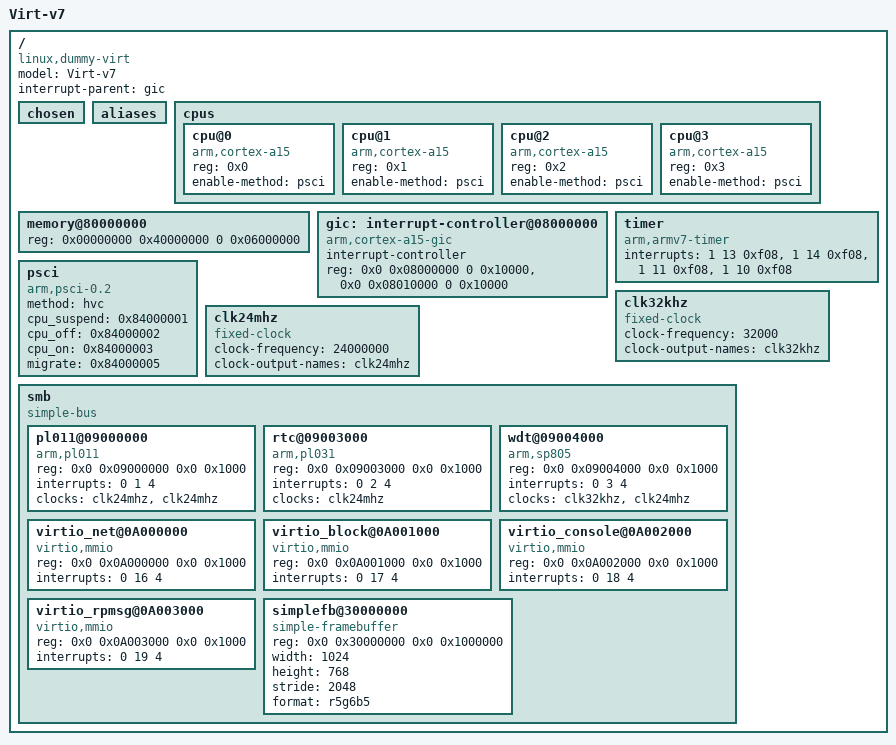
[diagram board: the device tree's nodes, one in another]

/dts-v1/;

/ {
	model = "Virt-v7";
	compatible = "linux,dummy-virt";
	interrupt-parent = <&gic>;
	#address-cells = <2>;
	#size-cells = <2>;

	chosen { };
	aliases { };

	cpus {
		#address-cells = <1>;
		#size-cells = <0>;

		cpu@0 {
			device_type = "cpu";
			compatible = "arm,cortex-a15";
			reg = <0x0>;
			enable-method = "psci";
		};
		cpu@1 {
			device_type = "cpu";
			compatible = "arm,cortex-a15";
			reg = <0x1>;
			enable-method = "psci";
		};
		cpu@2 {
			device_type = "cpu";
			compatible = "arm,cortex-a15";
			reg = <0x2>;
			enable-method = "psci";
		};
		cpu@3 {
			device_type = "cpu";
			compatible = "arm,cortex-a15";
			reg = <0x3>;
			enable-method = "psci";
		};
	};

	memory@80000000 {
		device_type = "memory";
		reg = <0x00000000 0x40000000 0 0x06000000>;
	};

	gic: interrupt-controller@08000000 {
		compatible = "arm,cortex-a15-gic";
		#interrupt-cells = <3>;
		#address-cells = <0>;
		interrupt-controller;
		reg = <0x0 0x08000000 0 0x10000>,
		      <0x0 0x08010000 0 0x10000>;
	};

	timer {
		compatible = "arm,armv7-timer";
		interrupts = <1 13 0xf08>,
			     <1 14 0xf08>,
			     <1 11 0xf08>,
			     <1 10 0xf08>;
	};

	psci {
		compatible = "arm,psci-0.2", "arm,psci";
		method = "hvc";
		cpu_suspend = <0x84000001>;
		cpu_off = <0x84000002>;
		cpu_on = <0x84000003>;
		migrate = <0x84000005>;
	};

	clk32khz: clk32khz {
		compatible = "fixed-clock";
		#clock-cells = <0x0>;
		clock-frequency = <32000>;
		clock-output-names = "clk32khz";
	};

	clk24mhz: clk24mhz {
		compatible = "fixed-clock";
		#clock-cells = <0x0>;
		clock-frequency = <24000000>;
		clock-output-names = "clk24mhz";
	};

	smb {
		compatible = "simple-bus";
		#address-cells = <2>;
		#size-cells = <2>;
		ranges;

		pl011@09000000 {
			compatible = "arm,pl011", "arm,primecell";
			reg = <0x0 0x09000000 0x0 0x1000>;
			interrupts = <0 1 4>;
			clocks = <&clk24mhz>, <&clk24mhz>;
			clock-names = "uartclk", "apb_pclk";
		};

		rtc@09003000 {
			compatible = "arm,pl031", "arm,primecell";
			reg = <0x0 0x09003000 0x0 0x1000>;
			interrupts = <0 2 4>;
			clocks = <&clk24mhz>;
			clock-names = "apb_pclk";
		};

		wdt@09004000 {
			compatible = "arm,sp805", "arm,primecell";
			reg = <0x0 0x09004000 0x0 0x1000>;
			interrupts = <0 3 4>;
			clocks = <&clk32khz>, <&clk24mhz>;
			clock-names = "wdogclk", "apb_pclk";
		};

		virtio_net@0A000000 {
			compatible = "virtio,mmio";
			reg = <0x0 0x0A000000 0x0 0x1000>;
			interrupts = <0 16 4>;
		};

		virtio_block@0A001000 {
			compatible = "virtio,mmio";
			reg = <0x0 0x0A001000 0x0 0x1000>;
			interrupts = <0 17 4>;
		};

		virtio_console@0A002000 {
			compatible = "virtio,mmio";
			reg = <0x0 0x0A002000 0x0 0x1000>;
			interrupts = <0 18 4>;
		};

		virtio_rpmsg@0A003000 {
			compatible = "virtio,mmio";
			reg = <0x0 0x0A003000 0x0 0x1000>;
			interrupts = <0 19 4>;
		};

		simplefb@30000000 {
			compatible = "simple-framebuffer";
			reg = <0x0 0x30000000 0x0 0x1000000>;
			width = <1024>;
			height = <768>;
			stride = <2048>;
			format = "r5g6b5";
		};
	};
};
